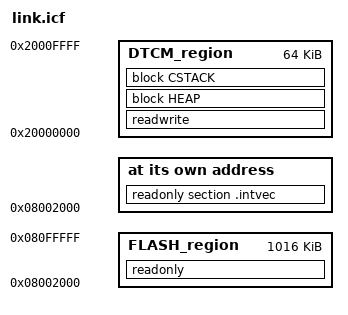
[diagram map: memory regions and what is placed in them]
/*###ICF### Section handled by ICF editor, don't touch! ****/
/*-Editor annotation file-*/
/* IcfEditorFile="$TOOLKIT_DIR$\config\ide\IcfEditor\cortex_v1_0.xml" */
/*-Specials-*/
define symbol __ICFEDIT_intvec_start__ = 0x08002000;
/*-Memory Regions-*/
define symbol __ICFEDIT_region_FLASH_start__ = 0x08002000;
define symbol __ICFEDIT_region_FLASH_end__   = 0x080FFFFF;
define symbol __ICFEDIT_region_DTCM_start__  = 0x20000000;
define symbol __ICFEDIT_region_DTCM_end__    = 0x2000FFFF;
/* SRAM1 is system heap at runtime (board.c), not linked here */
define symbol __ICFEDIT_region_SRAM1_start__ = 0x20010000;
define symbol __ICFEDIT_region_SRAM1_end__   = 0x2001FFFF;
/*-Sizes-*/
define symbol __ICFEDIT_size_cstack__ = 0x3000;
define symbol __ICFEDIT_size_heap__   = 0x0000; /* RT-Thread heap uses SRAM1 */
/**** End of ICF editor section. ###ICF###*/

define memory mem with size = 4G;
define region FLASH_region = mem:[from __ICFEDIT_region_FLASH_start__ to __ICFEDIT_region_FLASH_end__];
define region DTCM_region  = mem:[from __ICFEDIT_region_DTCM_start__  to __ICFEDIT_region_DTCM_end__];

define block CSTACK    with alignment = 8, size = __ICFEDIT_size_cstack__   { };
define block HEAP      with alignment = 8, size = __ICFEDIT_size_heap__     { };

initialize by copy { readwrite };
do not initialize  { section .noinit };

place at address mem:__ICFEDIT_intvec_start__ { readonly section .intvec };

place in FLASH_region { readonly };
/* CSTACK last in DTCM so MSP grows down from DTCM top; no RTT heap in DTCM */
place in DTCM_region  { readwrite, block HEAP, block CSTACK };

export symbol __ICFEDIT_region_DTCM_start__;
export symbol __ICFEDIT_region_DTCM_end__;
export symbol __ICFEDIT_region_SRAM1_start__;
export symbol __ICFEDIT_region_SRAM1_end__;
